# S6E2DH register map
File version: 1.1
CPU: CM4 r0p1, little endian, MPU, FPU, 4 interrupt priority bits
Registers are 32-bit, read-write, reset 0x0 unless marked. A register's access mark holds for its fields unless they carry their own. Offsets are from the block's base; [hi:lo] are bit positions.

## GDCSUB — GDC Subsystem control registers
Base 0xD0A00000
0x00 LockUnlock wo — Lock Protection Setting register
  [31:0] LockUnlock — Protection key of this address block setting bits
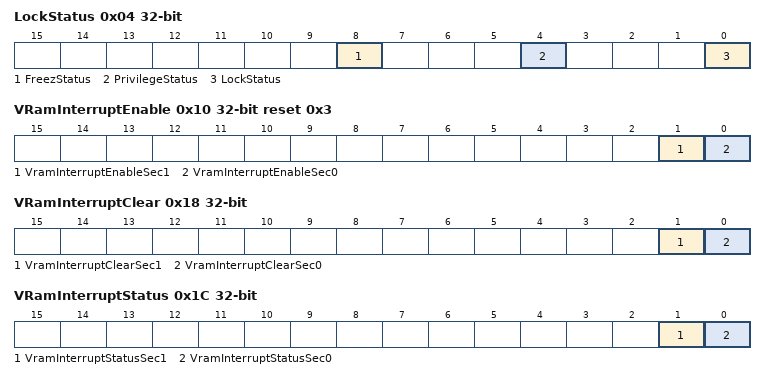
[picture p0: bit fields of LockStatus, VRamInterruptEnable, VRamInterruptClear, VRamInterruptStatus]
0x04 LockStatus ro — Lock Protection Status register
  [8] FreezStatus — Current status of freeze status
  [4] PrivilegeStatus — Current status of privilege protection
  [0] LockStatus — Current status of lock protection
0x0C ConfigClockControl reset 0x1
  [2:0] ConfigClockSelect — CONFIG Clock division ratio setting bits
0x10 VRamInterruptEnable reset 0x3 — VRAM ECC error interrupt enable/disable register
  [1] VramInterruptEnableSec1 — Interrupt control of VRAM ECC error for VRAM port1
  [0] VramInterruptEnableSec0 — Interrupt control of VRAM ECC error for VRAM port0
0x18 VRamInterruptClear wo — VRAM ECC error interrupt clear register
  [1] VramInterruptClearSec1 — Clear interrupt of VRAM ECC error for VRAM port1
  [0] VramInterruptClearSec0 — Clear interrupt of VRAM ECC error for VRAM port0
0x1C VRamInterruptStatus ro — VRAM ECC error interrupt status register
  [1] VramInterruptStatusSec1 — Indicator of VRAM Interrupt status for VRAM port1
  [0] VramInterruptStatusSec0 — Indicator of VRAM Interrupt status for VRAM port0
0x20 ExtFlashDevSelect reset 0x1 — External Flash Device Selection register
  [0] ExtFlashDevSelect — External memory device selection bit
0x24 VRamRemapDisable — VRAM Remap Mode Disable register
  [0] VramRemapDisable — VRAM address remap or non-remap selection bit
0x28 PanicSwitch — Panic display mode switch register
  [0] PanicSwitch — Panic display mode or Normal display mode selection bit
0x2C GDC_ClockDivider reset 0x40000 — GDC Clock Generation Control register
  [23:8] GDCClockSelect — GDC clock generation control bits
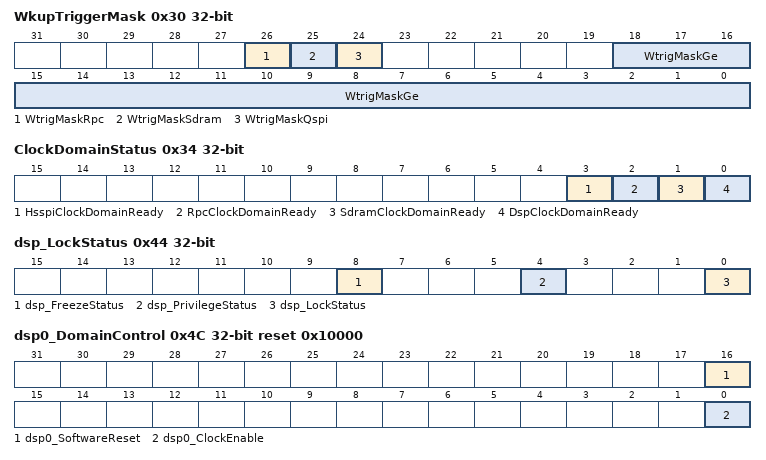
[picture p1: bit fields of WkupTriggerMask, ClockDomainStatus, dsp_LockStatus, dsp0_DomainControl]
0x30 WkupTriggerMask — CPU wake-up trigger Mask register
  [26] WtrigMaskRpc — Wake up trigger mask for HyperBus interface
  [25] WtrigMaskSdram — Wake up trigger mask for SDRAM interface
  [24] WtrigMaskQspi — Wake up trigger mask for QSPI interface
  [18:0] WtrigMaskGe — Wake up trigger mask for GDC Core
0x34 ClockDomainStatus — Clock Domain Status Indication register
  [3] HsspiClockDomainReady — Clock Status of QSPI interface clock domain
  [2] RpcClockDomainReady — Clock Status of HyperBus interface clock domain
  [1] SdramClockDomainReady — Clcok Status of SDRAM interface clock domain
  [0] DspClockDomainReady — Clock Status of Display clock domain
0x40 dsp_LockUnlock wo — Display LockUnlock register
  [31:0] dsp_LockUnlock — Protection key of this address block setting bits
0x44 dsp_LockStatus ro — Display Lock Status indication register
  [8] dsp_FreezeStatus — Current status of freeze status
  [4] dsp_PrivilegeStatus — Current status of provilege protection
  [0] dsp_LockStatus — 0
0x48 dsp0_ClockDivider reset 0x41E000 — Display Clock Divider Ration Setting Register
  [23:8] dsp0_ClockDivider — Division ration from the Reference clock for peripherals
0x4C dsp0_DomainControl reset 0x10000 — Display clock domain control register
  [16] dsp0_SoftwareReset — Display clock domain software reset
  [0] dsp0_ClockEnable — Display clock output control
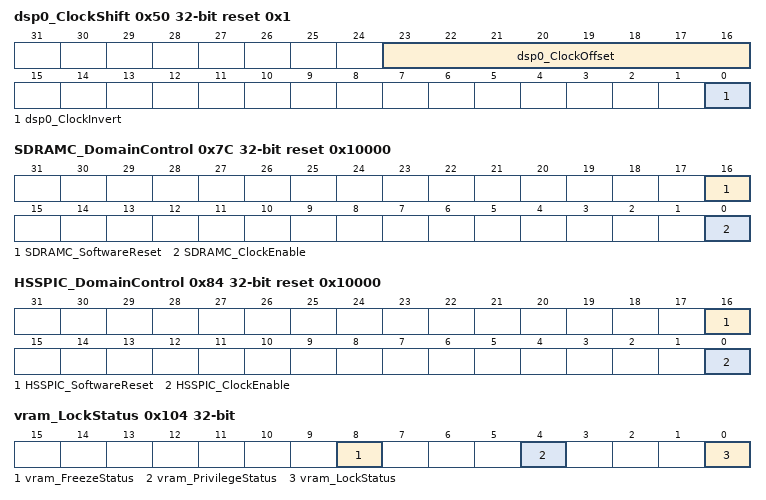
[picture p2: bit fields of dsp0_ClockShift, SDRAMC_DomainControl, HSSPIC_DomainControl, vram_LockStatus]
0x50 dsp0_ClockShift reset 0x1 — Register for display clock shift
  [23:16] dsp0_ClockOffset — Display clock phase setting bits
  [0] dsp0_ClockInvert — Display clock polarity setting bit
0x58 dsp0_PowerEnControl — Register for display Power Enable Signal Control
  [0] Power_Enable — Power control of external TFT panel setting bit
0x5C dsp0_ClockGateModeLock — Display Clock Gate Mode Protection Control register
  [31:0] LockUnlock — Protection of this address block setting bits
0x60 dsp0_ClockGateControl — Display Clock Gate Control register
  [0] ClockGate_Enable — Dot clock for external TFT panel control bit
0x78 SDRAMC_ClockDivider reset 0x40000 — Division Ratio of SDRAM interface setting register
  [23:8] SDRAMC_ClockDivider — Division ratio from the Reference clock for peripherals
0x7C SDRAMC_DomainControl reset 0x10000 — SDRAM interface clock domain setting register
  [16] SDRAMC_SoftwareReset — Software reset for SDRAM interface clock domain
  [0] SDRAMC_ClockEnable — SDRAM interface clock output control
0x80 HSSPIC_ClockDivider reset 0x40000 — Division Ratio of QSPI interface setting register
  [23:8] HSSPIC_ClockDivider — Division Ratio from the Reference clock for peripherals
0x84 HSSPIC_DomainControl reset 0x10000 — QSPI interface clock domain setting register
  [16] HSSPIC_SoftwareReset — Software reset for QSPI interface clock domain
  [0] HSSPIC_ClockEnable — QSPI interface clock output control
0x88 RPCC_ClockDivider — Division Ratio of HyperBus interface setting register
  [2:0] RPCC_ClockDivider — Division Ratio from the Reference clock for peripherals
0x8C RPCC_DomainControl reset 0x10000 — HyperBus interface clock domain setting register
  [0] RPCC_ClockEnable — HyperBus interface clock output control
0x100 vram_LockUnlock
  [31:0] vram_LockUnlock — $
0x104 vram_LockStatus ro — $
  [8] vram_FreezeStatus — Current status of freeze status
  [4] vram_PrivilegeStatus — Current status of previlege protection
  [0] vram_LockStatus — Current status of lock protection
0x108 vram_sram_select — Size of the ECC protected memory region selection register
  [11:0] vram_sram_select — Selects the size of the ECC protected region
0x13C vram_aberraddr_s0 ro — GDC bus address of the read access at S0 interface which had a single-bit ECC error
  [31:0] vram_aberraddr_s0 — Indicates address which had an ECC single bit error
0x140 vram_aberraddr_s1 ro — GDC bus address of the read access at S1 interface which had a single-bit ECC error
  [31:0] vram_aberraddr_s1 — Indicates address which had an ECC single bit error
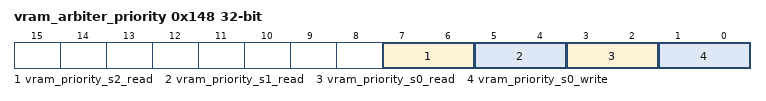
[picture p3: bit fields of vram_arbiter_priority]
0x148 vram_arbiter_priority — Register assigns fixed arbitration priorities to each GDC bus slave interface
  [7:6] vram_priority_s2_read — for internal device test purpose
  [5:4] vram_priority_s1_read — set priority of S1 interface for read
  [3:2] vram_priority_s0_read — set priority of S0 interface for read
  [1:0] vram_priority_s0_write — set priority of S0 interface for write
